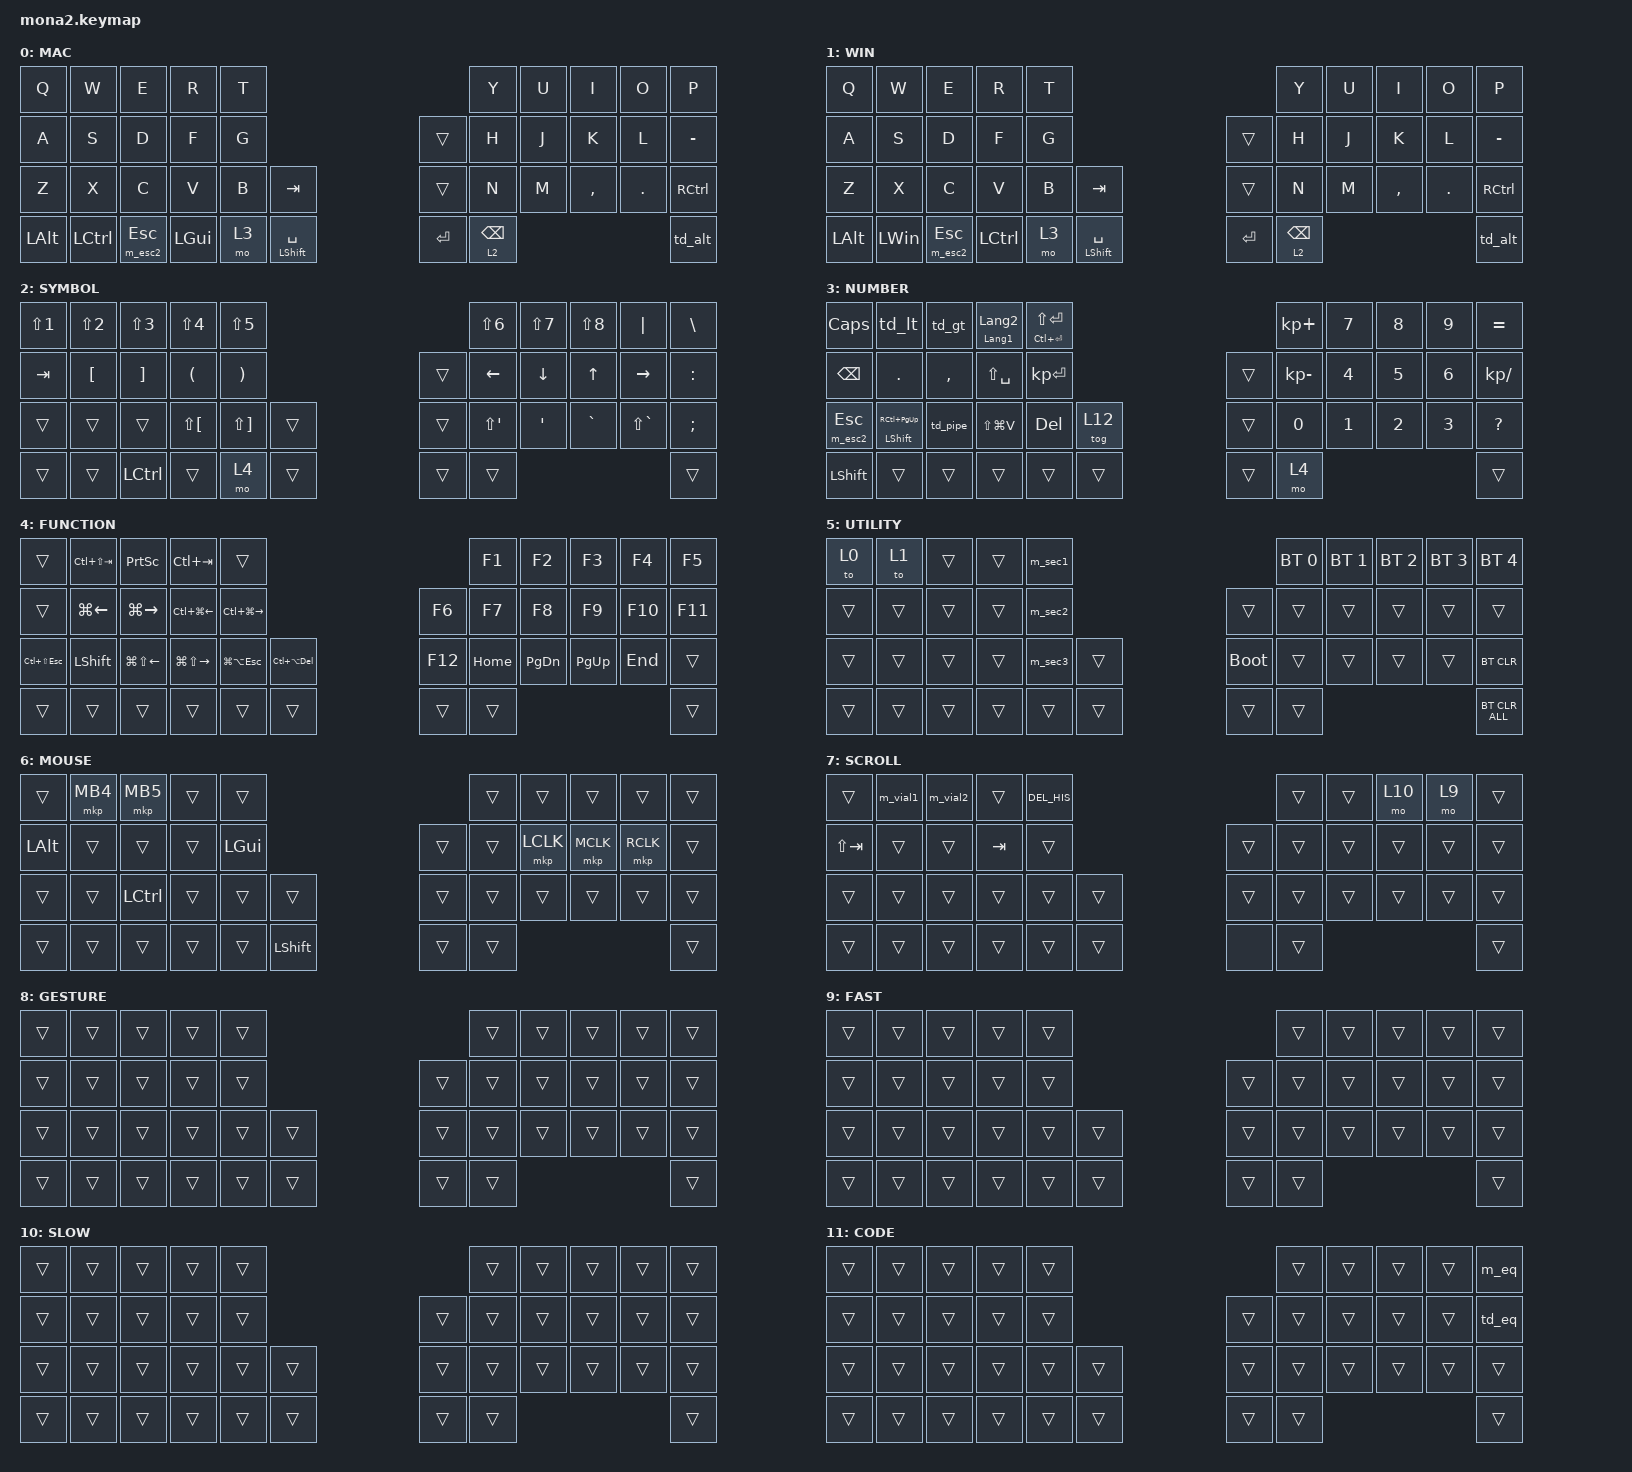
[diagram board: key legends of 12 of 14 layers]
#include <input/processors.dtsi>
#include <dt-bindings/zmk/input_transform.h>
#include <zephyr/dt-bindings/input/input-event-codes.h>
#include <behaviors.dtsi>
#include <dt-bindings/zmk/bt.h>
#include <dt-bindings/zmk/keys.h>
#include <dt-bindings/zmk/pointing.h>

#define ZMK_POINTING_DEFAULT_SCRL_VAL 300    // エンコーダー1トリガーあたりのスクロール量 (100→200→300: 体感調整、トラボ速度とは独立)

// 注意: レイヤー名のマクロ(#define WIN 1等)を定義しないこと。
// プリプロセッサがkeymapのレイヤーノード名まで数字に置換してしまい、
// BLEに乗るレイヤー名が壊れる(過去にWIN/MOUSE等が"1"/"6"になっていた)。

&mt {
    flavor = "tap-preferred";
    quick-tap-ms = <0>;
    tapping-term-ms = <150>;
};

&lt {
    quick-tap-ms = <200>;
    flavor = "hold-preferred";    // 別キー押下で即ホールド確定(お試し中)。タップ暴発が出たらbalancedへ戻す
    tapping-term-ms = <150>;
};

/ {
    combos {
        compatible = "zmk,combos";

        layer5_ESC {
            bindings = <&lt 5 ESC>;
            key-positions = <39 38>;
        };

        // ── Z+X系コンボのOS分岐 ──
        // 同一key-positionsにレイヤー排他の2枚を重ねる: 同じ指の動きでMAC=Ctrl / WIN=Alt。
        // コンボは「押した瞬間の最上位アクティブレイヤー」で判定されるため、
        // MACでNUMBER押下中=3、WINでNUMBER押下中=WIN_FIX(13)が最上位となり衝突しない。

        zx_mod_mac {
            bindings = <&kp LCTRL>;
            key-positions = <21 22>;
            layers = <0 3>;
            timeout-ms = <250>;
        };

        zx_mod_win {
            bindings = <&kp LEFT_ALT>;
            key-positions = <21 22>;
            layers = <1 13>;
            timeout-ms = <250>;
        };

        zxc_mod_mac {
            bindings = <&kp LS(LCTRL)>;
            key-positions = <21 22 23>;
            layers = <0 3>;
            timeout-ms = <250>;    // zx側と統一。Ctrl+Cは独立Ctrlキーを使う運用のためロール誤変換の懸念なし
        };

        zxc_mod_win {
            bindings = <&kp LS(LEFT_ALT)>;
            key-positions = <21 22 23>;
            layers = <1 13>;
            timeout-ms = <250>;    // 同上
        };

        esc_t_g {
            bindings = <&kp ESC>;
            key-positions = <4 14>;
            layers = <0 1>;
        };

        caps_word {
            bindings = <&caps_word>;
            key-positions = <11 10>;
            layers = <3 13>;    // 13=WIN_FIX: WINでNUMBER押下中は13が最上位になるため必須
        };

        // G+B(左手人差し指の縦ペア)同時押しでCODEレイヤーへ。esc_t_g(T+G)の1段下版

        code_layer {
            bindings = <&mo 11>;
            key-positions = <14 25>;
            layers = <0 1>;
            slow-release;    // 両方離すまでレイヤー維持
        };

        // Y+H(右手人差し指の縦ペア)でSCROLL(7)をトグル。左手T+G/G+Bと対称配置。
        // ベース/AML(6)中/SCROLL(7)中のどこからでも発動し、6⇄7の行き来を担う

        scroll_toggle {
            bindings = <&tog 7>;
            key-positions = <5 16>;
            layers = <0 1 6 7>;
        };
    };

    conditional_layers {
        compatible = "zmk,conditional-layers";

        win_fix {
            if-layers = <1 3>;
            then-layer = <13>;
        };
    };

    macros {
        to_layer_0: to_layer_0 {
            compatible = "zmk,behavior-macro-one-param";
            #binding-cells = <1>;
            bindings = <&to 0 &macro_param_1to1 &kp MACRO_PLACEHOLDER>;
            label = "TO_LAYER_0";
        };

        // ── cornix由来のテキストマクロ (前後スペース付きR演算子) ──

        m_pipe: m_pipe {
            compatible = "zmk,behavior-macro";
            #binding-cells = <0>;
            wait-ms = <0>;
            tap-ms = <5>;
            bindings = <&kp SPACE &kp PIPE &kp GT &kp SPACE>;    // " |> "
        };

        m_mpipe: m_mpipe {
            compatible = "zmk,behavior-macro";
            #binding-cells = <0>;
            wait-ms = <0>;
            tap-ms = <5>;
            bindings = <&kp SPACE &kp PRCNT &kp GT &kp PRCNT &kp SPACE>;    // " %>% "
        };

        m_eqeq: m_eqeq {
            compatible = "zmk,behavior-macro";
            #binding-cells = <0>;
            wait-ms = <0>;
            tap-ms = <5>;
            bindings = <&kp SPACE &kp EQUAL &kp EQUAL &kp SPACE>;    // " == "
        };

        m_neq: m_neq {
            compatible = "zmk,behavior-macro";
            #binding-cells = <0>;
            wait-ms = <0>;
            tap-ms = <5>;
            bindings = <&kp SPACE &kp EXCL &kp EQUAL &kp SPACE>;    // " != "
        };

        m_eq: m_eq {
            compatible = "zmk,behavior-macro";
            #binding-cells = <0>;
            wait-ms = <0>;
            tap-ms = <5>;
            bindings = <&kp SPACE &kp EQUAL &kp SPACE>;    // " = "
        };

        m_lt: m_lt {
            compatible = "zmk,behavior-macro";
            #binding-cells = <0>;
            wait-ms = <0>;
            tap-ms = <5>;
            bindings = <&kp SPACE &kp LT &kp SPACE>;    // " < "
        };

        m_le: m_le {
            compatible = "zmk,behavior-macro";
            #binding-cells = <0>;
            wait-ms = <0>;
            tap-ms = <5>;
            bindings = <&kp SPACE &kp LT &kp EQUAL &kp SPACE>;    // " <= "
        };

        m_larrow: m_larrow {
            compatible = "zmk,behavior-macro";
            #binding-cells = <0>;
            wait-ms = <0>;
            tap-ms = <5>;
            bindings = <&kp SPACE &kp LT &kp MINUS &kp SPACE>;    // " <- "
        };

        m_gt: m_gt {
            compatible = "zmk,behavior-macro";
            #binding-cells = <0>;
            wait-ms = <0>;
            tap-ms = <5>;
            bindings = <&kp SPACE &kp GT &kp SPACE>;    // " > "
        };

        m_ge: m_ge {
            compatible = "zmk,behavior-macro";
            #binding-cells = <0>;
            wait-ms = <0>;
            tap-ms = <5>;
            bindings = <&kp SPACE &kp GT &kp EQUAL &kp SPACE>;    // " >= "
        };

        m_rarrow: m_rarrow {
            compatible = "zmk,behavior-macro";
            #binding-cells = <0>;
            wait-ms = <0>;
            tap-ms = <5>;
            bindings = <&kp SPACE &kp MINUS &kp GT &kp SPACE>;    // " -> "
        };

        m_fatarrow: m_fatarrow {
            compatible = "zmk,behavior-macro";
            #binding-cells = <0>;
            wait-ms = <0>;
            tap-ms = <5>;
            bindings = <&kp SPACE &kp EQUAL &kp GT &kp SPACE>;    // " => "
        };

        m_esc2: m_esc2 {
            compatible = "zmk,behavior-macro";
            #binding-cells = <0>;
            wait-ms = <15>;
            tap-ms = <5>;
            bindings = <&kp ESC &kp ESC>;    // ESC×2 (Vim用)
        };

        // ── Vialから移植した操作マクロ (Enter/Up/Tabの定型操作) ──

        m_vial1: m_vial1 {
            compatible = "zmk,behavior-macro";
            #binding-cells = <0>;
            tap-ms = <10>;

            // Enter →200ms→ Up →200ms→ Enter →200ms→ Tab →200ms→ Tab (全間隔200ms)

            bindings =
                <&macro_wait_time 200>,
                <&kp ENTER &kp UP &kp ENTER &kp TAB &kp TAB>;
        };

        m_vial2: m_vial2 {
            compatible = "zmk,behavior-macro";
            #binding-cells = <0>;
            tap-ms = <10>;

            // Enter →200ms→ Up,Up →200ms→ Enter →150ms→ Tab,Tab

            bindings =
                <&macro_wait_time 200>,
                <&kp ENTER>,
                <&macro_wait_time 10>,
                <&kp UP>,
                <&macro_wait_time 200>,
                <&kp UP>,
                <&macro_wait_time 150>,
                <&kp ENTER>,
                <&macro_wait_time 10>,
                <&kp TAB &kp TAB>;
        };

        // 旧m_vial3を拡張 (2026-09-11): 末尾に Tab, Tab を追加
        // Enter →150ms→ Down →150ms→ Enter →150ms→ Tab →100ms→ Tab →100ms→ Tab →150ms
        // (macro_wait_timeは「直後のタップの後に待つ時間」を設定する)

        DEL_HIS: DEL_HIS {
            compatible = "zmk,behavior-macro";
            #binding-cells = <0>;
            tap-ms = <10>;
            bindings =
                <&macro_wait_time 150>,
                <&kp ENTER &kp DOWN &kp ENTER>,
                <&macro_wait_time 100>,
                <&kp TAB &kp TAB>,
                <&macro_wait_time 150>,
                <&kp TAB>;
        };

        // ── MACROレイヤー用マクロ (m_mcrN連番) ──

        m_mcr1: m_mcr1 {
            compatible = "zmk,behavior-macro";
            #binding-cells = <0>;
            wait-ms = <10>;
            tap-ms = <10>;

            // Ctrl+Shift+Fタップ → 250ms → Ctrl+Shift+Qタップ
            // (ディレイ200→250: ショートカットの反応待ち)

            bindings =
                <&macro_tap>,
                <&kp LC(LS(F))>,
                <&macro_wait_time 250>,
                <&macro_tap>,
                <&kp LC(LS(Q))>;
        };

        // ── シークレット定型文 (中身はローカルのsecrets.dtsi側。CIビルドでは何もしない) ──

        m_sec1: m_sec1 {
            compatible = "zmk,behavior-macro";
            #binding-cells = <0>;
            bindings = <&sec1_impl>;
        };

        m_sec2: m_sec2 {
            compatible = "zmk,behavior-macro";
            #binding-cells = <0>;
            bindings = <&sec2_impl>;
        };

        m_sec3: m_sec3 {
            compatible = "zmk,behavior-macro";
            #binding-cells = <0>;
            bindings = <&sec3_impl>;
        };

        m_sec4: m_sec4 {
            compatible = "zmk,behavior-macro";
            #binding-cells = <0>;
            bindings = <&sec4_impl>;
        };

        m_sec5: m_sec5 {
            compatible = "zmk,behavior-macro";
            #binding-cells = <0>;
            bindings = <&sec5_impl>;
        };

        m_sec6: m_sec6 {
            compatible = "zmk,behavior-macro";
            #binding-cells = <0>;
            bindings = <&sec6_impl>;
        };

        m_sec7: m_sec7 {
            compatible = "zmk,behavior-macro";
            #binding-cells = <0>;
            bindings = <&sec7_impl>;
        };

        m_sec8: m_sec8 {
            compatible = "zmk,behavior-macro";
            #binding-cells = <0>;
            bindings = <&sec8_impl>;
        };
    };

    behaviors {
        lt_to_layer_0: lt_to_layer_0 {
            compatible = "zmk,behavior-hold-tap";
            label = "LAYER_TAP_TO_0";
            bindings = <&mo>, <&to_layer_0>;

            #binding-cells = <2>;
            tapping-term-ms = <200>;
        };

        scroll_up_down: mouse_wheel_up_down {
            compatible = "zmk,behavior-sensor-rotate";
            #sensor-binding-cells = <0>;
            bindings = <&msc SCRL_DOWN>, <&msc SCRL_UP>;

            tap-ms = <20>;
        };

        scroll_right_left: mouse_wheel_right_left {
            compatible = "zmk,behavior-sensor-rotate";
            #sensor-binding-cells = <0>;
            bindings = <&msc SCRL_LEFT>, <&msc SCRL_RIGHT>;

            tap-ms = <20>;
        };

        // 親指Shift/Space専用hold-tap。
        // グローバル&mt(tap-preferred)だと「他キー割り込みではholdにならない」ため、
        // 高速ロールで"_"(Shift+MINUS)が「␣-」化していた。balancedは
        // 「押下中に他キーがタップされたらhold確定」なので流れの中でShiftが効く。
        // quick-tap: タップ直後の再押下ホールドはShiftでなくSpaceリピートになる

        mt_spc: mt_spc {
            compatible = "zmk,behavior-hold-tap";
            #binding-cells = <2>;
            flavor = "balanced";
            tapping-term-ms = <150>;
            quick-tap-ms = <200>;
            bindings = <&kp>, <&kp>;
        };

        // ── cornix由来のhold-tap ──
        // 汎用: ホールド=キーコード / タップ=キーコード。例: &ht_kp F2 RC(PAGE_UP)
        // (旧ht250。tapping termは他と揃えて150msに変更)

        ht_kp: ht_kp {
            compatible = "zmk,behavior-hold-tap";
            #binding-cells = <2>;
            flavor = "tap-preferred";
            tapping-term-ms = <150>;
            bindings = <&kp>, <&kp>;
        };

        // TD10用: タップ=キーコード / ホールド=ESC×2。使い方: &ht_esc 0 ESC

        ht_esc: ht_esc {
            compatible = "zmk,behavior-hold-tap";
            #binding-cells = <2>;
            flavor = "tap-preferred";
            tapping-term-ms = <150>;
            bindings = <&m_esc2>, <&kp>;
        };

        // td_pipeの1段目: タップ=キーコード / ホールド=" |> "。使い方: &ht_pipe 0 LC(PG_DN)

        ht_pipe: ht_pipe {
            compatible = "zmk,behavior-hold-tap";
            #binding-cells = <2>;
            flavor = "tap-preferred";
            tapping-term-ms = <150>;
            bindings = <&m_pipe>, <&kp>;
        };

        // td_ltの1段目: タップ=" < " / ホールド=" <= "。使い方: &ht_le 0 0

        ht_le: ht_le {
            compatible = "zmk,behavior-hold-tap";
            #binding-cells = <2>;
            flavor = "tap-preferred";
            tapping-term-ms = <150>;
            bindings = <&m_le>, <&m_lt>;
        };

        // td_gtの1段目: タップ=" > " / ホールド=" >= "。使い方: &ht_ge 0 0

        ht_ge: ht_ge {
            compatible = "zmk,behavior-hold-tap";
            #binding-cells = <2>;
            flavor = "tap-preferred";
            tapping-term-ms = <150>;
            bindings = <&m_ge>, <&m_gt>;
        };

        // td_gtの2段目: タップ=" -> " / ホールド=" => "。使い方: &ht_arrows 0 0

        ht_arrows: ht_arrows {
            compatible = "zmk,behavior-hold-tap";
            #binding-cells = <2>;
            flavor = "tap-preferred";
            tapping-term-ms = <150>;
            bindings = <&m_fatarrow>, <&m_rarrow>;
        };

        // ── cornix由来のtap-dance ──
        // TD1: タップ=Ctrl+PgDn / ホールド=" |> " / 2回タップ=" %>% "

        td_pipe: td_pipe {
            compatible = "zmk,behavior-tap-dance";
            #binding-cells = <0>;
            tapping-term-ms = <150>;
            bindings = <&ht_pipe 0 LC(PG_DN)>, <&m_mpipe>;
        };

        // TD4: タップ=" < " / ホールド=" <= " / 2回タップ=" <- "

        td_lt: td_lt {
            compatible = "zmk,behavior-tap-dance";
            #binding-cells = <0>;
            tapping-term-ms = <150>;
            bindings = <&ht_le 0 0>, <&m_larrow>;
        };

        // TD5: タップ=" > " / ホールド=" >= " / 2回タップ=" -> " / 2回タップ+ホールド=" => "

        td_gt: td_gt {
            compatible = "zmk,behavior-tap-dance";
            #binding-cells = <0>;
            tapping-term-ms = <150>;
            bindings = <&ht_ge 0 0>, <&ht_arrows 0 0>;
        };

        // ホールド=キーコード / タップ=無効 (td_altの2打目スロット用)

        ht_hold_kp: ht_hold_kp {
            compatible = "zmk,behavior-hold-tap";
            #binding-cells = <2>;
            flavor = "tap-preferred";
            tapping-term-ms = <150>;
            bindings = <&kp>, <&none>;
        };

        // 41番(右端下)用: タップ=Cmd+Space / ホールド=Alt / 2回タップ=無効 / タップ+ホールド=LCtrl+Alt
        // td_gtと同じ「タップダンス×ホールドタップ」入れ子パターン

        td_alt: td_alt {
            compatible = "zmk,behavior-tap-dance";
            #binding-cells = <0>;
            tapping-term-ms = <200>;
            bindings = <&ht_kp LALT LG(SPACE)>, <&ht_hold_kp LC(LALT) 0>;
        };

        // TD9: タップ=" == " / 2回タップ=" != "

        td_eq: td_eq {
            compatible = "zmk,behavior-tap-dance";
            #binding-cells = <0>;
            tapping-term-ms = <250>;    // 150はダブルタップにシビアすぎた。1回タップの確定待ちも250msになる点は仕様
            bindings = <&m_eqeq>, <&m_neq>;
        };
    };

    keymap {
        compatible = "zmk,keymap";

        MAC {
            bindings = <
&kp Q     &kp W      &kp E          &kp R         &kp T                                         &kp Y            &kp U  &kp I      &kp O    &kp P
&kp A     &kp S      &kp D          &kp F         &kp G                              &trans     &kp H            &kp J  &kp K      &kp L    &kp MINUS
&kp Z     &kp X      &kp C          &kp V         &kp B  &kp TAB                     &trans     &kp N            &kp M  &kp COMMA  &kp DOT  &kp RCTRL
&kp LALT  &kp LCTRL  &ht_esc 0 ESC  &kp LEFT_GUI  &mo 3  &mt_spc LEFT_SHIFT SPACE    &kp ENTER  &lt 2 BACKSPACE                             &td_alt
            >;

            sensor-bindings = <&scroll_up_down>;
        };

        WIN {
            bindings = <
&kp Q     &kp W         &kp E          &kp R             &kp T                                         &kp Y            &kp U  &kp I      &kp O    &kp P
&kp A     &kp S         &kp D          &kp F             &kp G                              &trans     &kp H            &kp J  &kp K      &kp L    &kp MINUS
&kp Z     &kp X         &kp C          &kp V             &kp B  &kp TAB                     &trans     &kp N            &kp M  &kp COMMA  &kp DOT  &kp RCTRL
&kp LALT  &kp LEFT_WIN  &ht_esc 0 ESC  &kp LEFT_CONTROL  &mo 3  &mt_spc LEFT_SHIFT SPACE    &kp ENTER  &lt 2 BACKSPACE                             &td_alt
            >;

            sensor-bindings = <&scroll_up_down>;
        };

        SYMBOL {
            bindings = <
&kp LS(NUMBER_1)  &kp LS(NUMBER_2)  &kp LS(NUMBER_3)  &kp LS(NUMBER_4)      &kp LS(NUMBER_5)                         &kp LS(NUMBER_6)      &kp LS(NUMBER_7)  &kp LS(NUMBER_8)  &kp PIPE       &kp BACKSLASH
&kp TAB           &kp LBKT          &kp RBKT          &kp LEFT_PARENTHESIS  &kp RIGHT_PARENTHESIS            &trans  &kp LEFT              &kp DOWN          &kp UP            &kp RIGHT      &kp COLON
&trans            &trans            &trans            &kp LS(LEFT_BRACKET)  &kp LS(RIGHT_BRACKET)  &trans    &trans  &kp LS(SINGLE_QUOTE)  &kp SINGLE_QUOTE  &kp GRAVE         &kp LS(GRAVE)  &kp SEMI
&trans            &trans            &kp LCTRL         &trans                &mo 4                  &trans    &trans  &trans                                                                   &trans
            >;

            sensor-bindings = <&scroll_right_left>;
        };

        NUMBER {
            bindings = <
&kp CAPS        &td_lt                         &td_gt     &mt LANGUAGE_1 LANGUAGE_2  &mt LC(ENTER) LS(ENTER)                     &kp KP_PLUS   &kp NUMBER_7  &kp NUMBER_8  &kp NUMBER_9  &kp EQUAL
&kp BACKSPACE   &kp DOT                        &kp COMMA  &kp LS(SPACE)              &kp KP_ENTER                        &trans  &kp KP_MINUS  &kp NUMBER_4  &kp NUMBER_5  &kp NUMBER_6  &kp KP_SLASH
&ht_esc 0 ESC   &ht_kp LEFT_SHIFT RC(PAGE_UP)  &td_pipe   &kp LS(LG(V))              &kp DEL                  &tog 12    &trans  &kp NUMBER_0  &kp NUMBER_1  &kp NUMBER_2  &kp NUMBER_3  &kp QUESTION
&kp LEFT_SHIFT  &trans                         &trans     &trans                     &trans                   &trans     &trans  &mo 4                                                   &trans
            >;

            sensor-bindings = <&inc_dec_kp K_VOLUME_DOWN K_VOLUME_UP>;
        };

        FUNCTION {
            bindings = <
&trans           &kp LC(LS(TAB))     &kp PRINTSCREEN         &kp LC(TAB)              &trans                                               &kp F1    &kp F2         &kp F3       &kp F4   &kp F5
&trans           &kp LG(LEFT_ARROW)  &kp LG(RIGHT_ARROW)     &kp LC(LG(LEFT_ARROW))   &kp LC(LG(RIGHT_ARROW))                     &kp F6   &kp F7    &kp F8         &kp F9       &kp F10  &kp F11
&kp LC(LS(ESC))  &kp LEFT_SHIFT      &kp LG(LS(LEFT_ARROW))  &kp LG(LS(RIGHT_ARROW))  &kp LG(LA(ESC))          &kp LC(LA(DEL))    &kp F12  &kp HOME  &kp PAGE_DOWN  &kp PAGE_UP  &kp END  &trans
&trans           &trans              &trans                  &trans                   &trans                   &trans             &trans   &trans                                         &trans
            >;

            sensor-bindings = <&inc_dec_kp C_VOL_DN C_VOL_UP>;
        };

        UTILITY {
            bindings = <
&to 0   &to 1   &trans  &trans  &m_sec1                         &bt BT_SEL 0  &bt BT_SEL 1  &bt BT_SEL 2  &bt BT_SEL 3  &bt BT_SEL 4
&trans  &trans  &trans  &trans  &m_sec2            &trans       &trans        &trans        &trans        &trans        &trans
&trans  &trans  &trans  &trans  &m_sec3  &trans    &bootloader  &trans        &trans        &trans        &trans        &bt BT_CLR
&trans  &trans  &trans  &trans  &trans   &trans    &trans       &trans                                                  &bt BT_CLR_ALL
            >;

            sensor-bindings = <&scroll_up_down>;
        };

        MOUSE {
            bindings = <
&trans    &mkp MB4  &mkp MB5   &trans  &trans                         &trans  &trans     &trans     &trans     &trans
&kp LALT  &trans    &trans     &trans  &kp LGUI               &trans  &trans  &mkp LCLK  &mkp MCLK  &mkp RCLK  &trans
&trans    &trans    &kp LCTRL  &trans  &trans    &trans       &trans  &trans  &trans     &trans     &trans     &trans
&trans    &trans    &trans     &trans  &trans    &kp LSHFT    &trans  &trans                                   &trans
            >;

            sensor-bindings = <&scroll_up_down>;
        };

        SCROLL {
            bindings = <
&trans       &m_vial1  &m_vial2  &trans   &DEL_HIS                    &trans  &trans  &mo 10  &mo 9   &trans
&kp LS(TAB)  &trans    &trans    &kp TAB  &trans              &trans  &trans  &trans  &trans  &trans  &trans
&trans       &trans    &trans    &trans   &trans    &trans    &trans  &trans  &trans  &trans  &trans  &trans
&trans       &trans    &trans    &trans   &trans    &trans    &none   &trans                          &trans
            >;

            sensor-bindings = <&scroll_up_down>;
        };

        GESTURE {
            bindings = <
&trans  &trans  &trans  &trans  &trans                    &trans  &trans  &trans  &trans  &trans
&trans  &trans  &trans  &trans  &trans            &trans  &trans  &trans  &trans  &trans  &trans
&trans  &trans  &trans  &trans  &trans  &trans    &trans  &trans  &trans  &trans  &trans  &trans
&trans  &trans  &trans  &trans  &trans  &trans    &trans  &trans                          &trans
            >;
        };

        FAST {
            bindings = <
&trans  &trans  &trans  &trans  &trans                    &trans  &trans  &trans  &trans  &trans
&trans  &trans  &trans  &trans  &trans            &trans  &trans  &trans  &trans  &trans  &trans
&trans  &trans  &trans  &trans  &trans  &trans    &trans  &trans  &trans  &trans  &trans  &trans
&trans  &trans  &trans  &trans  &trans  &trans    &trans  &trans                          &trans
            >;
        };

        SLOW {
            bindings = <
&trans  &trans  &trans  &trans  &trans                    &trans  &trans  &trans  &trans  &trans
&trans  &trans  &trans  &trans  &trans            &trans  &trans  &trans  &trans  &trans  &trans
&trans  &trans  &trans  &trans  &trans  &trans    &trans  &trans  &trans  &trans  &trans  &trans
&trans  &trans  &trans  &trans  &trans  &trans    &trans  &trans                          &trans
            >;
        };

        CODE {
            bindings = <
&trans  &trans  &trans  &trans  &trans                    &trans  &trans  &trans  &trans  &m_eq
&trans  &trans  &trans  &trans  &trans            &trans  &trans  &trans  &trans  &trans  &td_eq
&trans  &trans  &trans  &trans  &trans  &trans    &trans  &trans  &trans  &trans  &trans  &trans
&trans  &trans  &trans  &trans  &trans  &trans    &trans  &trans                          &trans
            >;
        };

        MACRO {
            bindings = <
&trans    &trans    &trans   &trans     &trans                     &trans  &trans  &trans  &trans  &trans
&kp LEFT  &kp DOWN  &kp UP   &kp RIGHT  &trans             &trans  &trans  &trans  &trans  &trans  &trans
&trans    &trans    &trans   &trans     &trans  &tog 12    &trans  &trans  &trans  &trans  &trans  &trans
&trans    &trans    &m_mcr1  &trans     &trans  &trans     &trans  &trans                          &trans
            >;
        };

        WIN_FIX {
            bindings = <
&trans  &trans  &trans  &mt LANGUAGE_1 LANGUAGE_2  &trans                    &trans  &trans  &trans  &trans  &trans
&trans  &trans  &trans  &trans                     &trans            &trans  &trans  &trans  &trans  &trans  &trans
&trans  &trans  &trans  &kp LS(LC(V))              &trans  &trans    &trans  &trans  &trans  &trans  &trans  &trans
&trans  &trans  &trans  &trans                     &trans  &trans    &trans  &trans                          &trans
            >;
        };
    };
};
